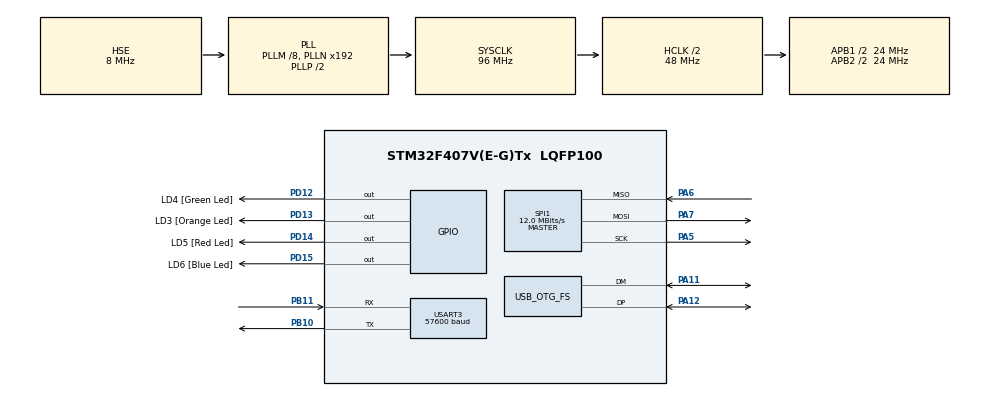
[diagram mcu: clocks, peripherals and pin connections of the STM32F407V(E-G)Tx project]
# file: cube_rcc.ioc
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Mcu.Family=STM32F4
Mcu.Name=STM32F407V(E-G)Tx
Mcu.Package=LQFP100
NVIC.PriorityGroup=NVIC_PRIORITYGROUP_0
PA11.Mode=Host_Only
PA11.Signal=USB_OTG_FS_DM
PA12.Mode=Host_Only
PA12.Signal=USB_OTG_FS_DP
PA5.Mode=Full_Duplex_Master
PA5.Signal=SPI1_SCK
PA6.Mode=Full_Duplex_Master
PA6.Signal=SPI1_MISO
PA7.Mode=Full_Duplex_Master
PA7.Signal=SPI1_MOSI
PB10.Mode=Asynchronous
PB10.Signal=USART3_TX
PB11.Mode=Asynchronous
PB11.Signal=USART3_RX
PD12.GPIO_Label=LD4 [Green Led]
PD12.GPIO_PuPd=GPIO_NOPULL
PD12.GPIO_Speed=GPIO_SPEED_FREQ_LOW
PD12.Signal=GPIO_Output
PD13.GPIO_Label=LD3 [Orange Led]
PD13.GPIO_PuPd=GPIO_NOPULL
PD13.GPIO_Speed=GPIO_SPEED_FREQ_LOW
PD13.Signal=GPIO_Output
PD14.GPIO_Label=LD5 [Red Led]
PD14.GPIO_PuPd=GPIO_NOPULL
PD14.GPIO_Speed=GPIO_SPEED_FREQ_LOW
PD14.Signal=GPIO_Output
PD15.GPIO_Label=LD6 [Blue Led]
PD15.GPIO_PuPd=GPIO_NOPULL
PD15.GPIO_Speed=GPIO_SPEED_FREQ_LOW
PD15.Signal=GPIO_Output
PH0-OSC_IN.GPIO_Label=PH0-OSC_IN
PH0-OSC_IN.Mode=HSE-External-Oscillator
PH0-OSC_IN.Signal=RCC_OSC_IN
PH1-OSC_OUT.GPIO_Label=PH1-OSC_OUT
PH1-OSC_OUT.Mode=HSE-External-Oscillator
PH1-OSC_OUT.Signal=RCC_OSC_OUT
ProjectManager.HeapSize=0x200
ProjectManager.StackSize=0x400
ProjectManager.TargetToolchain=STM32CubeIDE
RCC.48MHZClocksFreq_Value=48000000
RCC.AHBCLKDivider=RCC_SYSCLK_DIV2
RCC.AHBFreq_Value=48000000
RCC.APB1CLKDivider=RCC_HCLK_DIV2
RCC.APB1Freq_Value=24000000
RCC.APB1TimFreq_Value=48000000
RCC.APB2CLKDivider=RCC_HCLK_DIV2
RCC.APB2Freq_Value=24000000
RCC.APB2TimFreq_Value=48000000
RCC.CortexFreq_Value=48000000
RCC.HCLKFreq_Value=48000000
RCC.HSE_VALUE=8000000
RCC.HSI_VALUE=16000000
RCC.LSE_VALUE=32768
RCC.PLLM=8
RCC.SYSCLKFreq_VALUE=96000000
RCC.SYSCLKSource=RCC_SYSCLKSOURCE_PLLCLK
RCC.VCOOutputFreq_Value=192000000
SPI1.CalculateBaudRate=12.0 MBits/s
SPI1.Direction=SPI_DIRECTION_2LINES
SPI1.Mode=SPI_MODE_MASTER
SPI1.VirtualType=VM_MASTER
USART3.BaudRate=57600
USART3.VirtualMode=VM_ASYNC
USB_OTG_FS.VirtualMode=Host_Only
USB_OTG_FS.phy_itface=HCD_PHY_EMBEDDED
board=STM32F407G-DISC1

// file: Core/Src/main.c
/* USER CODE BEGIN Header */
/**
  ******************************************************************************
  * @file           : main.c
  * @brief          : Main program body
  ******************************************************************************
  * @attention
  *
  * <h2><center>&copy; Copyright (c) 2020 STMicroelectronics.
  * All rights reserved.</center></h2>
  *
  * This software component is licensed by ST under Ultimate Liberty license
  * SLA0044, the "License"; You may not use this file except in compliance with
  * the License. You may obtain a copy of the License at:
  *                             www.st.com/SLA0044
  *
  ******************************************************************************
  */
/* USER CODE END Header */

#include "main.h"

/* USER CODE BEGIN Includes */
#include "stdio.h"
#include "string.h"
/* USER CODE END Includes */

SPI_HandleTypeDef hspi1;

UART_HandleTypeDef huart3;

HCD_HandleTypeDef hhcd_USB_OTG_FS;

/* USER CODE BEGIN PV */
char msg_UART_TX [50];
/* USER CODE END PV */

void SystemClock_Config(void);
static void MX_GPIO_Init(void);
static void MX_USART3_UART_Init(void);
static void MX_USB_OTG_FS_HCD_Init(void);
static void MX_SPI1_Init(void);

int main(void)
{

  /* MCU Configuration--------------------------------------------------------*/

  /* Reset of all peripherals, Initializes the Flash interface and the Systick. */
  HAL_Init();

  /* Configure the system clock */
  SystemClock_Config();

  /* Initialize all configured peripherals */
  MX_GPIO_Init();
  MX_USART3_UART_Init();
  MX_USB_OTG_FS_HCD_Init();
  MX_SPI1_Init();
  /* USER CODE BEGIN 2 */
//  RCC_ClocksTypeDef RCC_Clocks;
  /* USER CODE END 2 */

  /* Infinite loop */
  while (1)
  {

    /* USER CODE BEGIN 3 */
	sprintf (msg_UART_TX, "%lu, %lu, %lu, %lu\r\n", HAL_RCC_GetSysClockFreq(), HAL_RCC_GetHCLKFreq(), HAL_RCC_GetPCLK1Freq(), HAL_RCC_GetPCLK2Freq());
	HAL_UART_Transmit (&huart3, (uint8_t*)msg_UART_TX, strlen(msg_UART_TX), 0xFF);
	HAL_Delay (1000);
  }
  /* USER CODE END 3 */
}

void SystemClock_Config(void)
{
  RCC_OscInitTypeDef RCC_OscInitStruct = {0};
  RCC_ClkInitTypeDef RCC_ClkInitStruct = {0};

  /** Configure the main internal regulator output voltage
  */
  __HAL_RCC_PWR_CLK_ENABLE();
  __HAL_PWR_VOLTAGESCALING_CONFIG(PWR_REGULATOR_VOLTAGE_SCALE1);
  /** Initializes the CPU, AHB and APB busses clocks
  */
  RCC_OscInitStruct.OscillatorType = RCC_OSCILLATORTYPE_HSE;
  RCC_OscInitStruct.HSEState = RCC_HSE_ON;
  RCC_OscInitStruct.PLL.PLLState = RCC_PLL_ON;
  RCC_OscInitStruct.PLL.PLLSource = RCC_PLLSOURCE_HSE;
  RCC_OscInitStruct.PLL.PLLM = 8;
  RCC_OscInitStruct.PLL.PLLN = 192;
  RCC_OscInitStruct.PLL.PLLP = RCC_PLLP_DIV2;
  RCC_OscInitStruct.PLL.PLLQ = 4;
  if (HAL_RCC_OscConfig(&RCC_OscInitStruct) != HAL_OK)
  {
    Error_Handler();
  }
  /** Initializes the CPU, AHB and APB busses clocks
  */
  RCC_ClkInitStruct.ClockType = RCC_CLOCKTYPE_HCLK|RCC_CLOCKTYPE_SYSCLK
                              |RCC_CLOCKTYPE_PCLK1|RCC_CLOCKTYPE_PCLK2;
  RCC_ClkInitStruct.SYSCLKSource = RCC_SYSCLKSOURCE_PLLCLK;
  RCC_ClkInitStruct.AHBCLKDivider = RCC_SYSCLK_DIV2;
  RCC_ClkInitStruct.APB1CLKDivider = RCC_HCLK_DIV2;
  RCC_ClkInitStruct.APB2CLKDivider = RCC_HCLK_DIV2;

  if (HAL_RCC_ClockConfig(&RCC_ClkInitStruct, FLASH_LATENCY_1) != HAL_OK)
  {
    Error_Handler();
  }
}

static void MX_SPI1_Init(void)
{

  /* SPI1 parameter configuration*/
  hspi1.Instance = SPI1;
  hspi1.Init.Mode = SPI_MODE_MASTER;
  hspi1.Init.Direction = SPI_DIRECTION_2LINES;
  hspi1.Init.DataSize = SPI_DATASIZE_8BIT;
  hspi1.Init.CLKPolarity = SPI_POLARITY_LOW;
  hspi1.Init.CLKPhase = SPI_PHASE_1EDGE;
  hspi1.Init.NSS = SPI_NSS_SOFT;
  hspi1.Init.BaudRatePrescaler = SPI_BAUDRATEPRESCALER_2;
  hspi1.Init.FirstBit = SPI_FIRSTBIT_MSB;
  hspi1.Init.TIMode = SPI_TIMODE_DISABLE;
  hspi1.Init.CRCCalculation = SPI_CRCCALCULATION_DISABLE;
  hspi1.Init.CRCPolynomial = 10;
  if (HAL_SPI_Init(&hspi1) != HAL_OK)
  {
    Error_Handler();
  }

}

static void MX_USART3_UART_Init(void)
{

  huart3.Instance = USART3;
  huart3.Init.BaudRate = 57600;
  huart3.Init.WordLength = UART_WORDLENGTH_8B;
  huart3.Init.StopBits = UART_STOPBITS_1;
  huart3.Init.Parity = UART_PARITY_NONE;
  huart3.Init.Mode = UART_MODE_TX_RX;
  huart3.Init.HwFlowCtl = UART_HWCONTROL_NONE;
  huart3.Init.OverSampling = UART_OVERSAMPLING_16;
  if (HAL_UART_Init(&huart3) != HAL_OK)
  {
    Error_Handler();
  }

}

static void MX_USB_OTG_FS_HCD_Init(void)
{

  hhcd_USB_OTG_FS.Instance = USB_OTG_FS;
  hhcd_USB_OTG_FS.Init.Host_channels = 8;
  hhcd_USB_OTG_FS.Init.speed = HCD_SPEED_FULL;
  hhcd_USB_OTG_FS.Init.dma_enable = DISABLE;
  hhcd_USB_OTG_FS.Init.phy_itface = HCD_PHY_EMBEDDED;
  hhcd_USB_OTG_FS.Init.Sof_enable = DISABLE;
  if (HAL_HCD_Init(&hhcd_USB_OTG_FS) != HAL_OK)
  {
    Error_Handler();
  }

}

static void MX_GPIO_Init(void)
{
  GPIO_InitTypeDef GPIO_InitStruct = {0};

  /* GPIO Ports Clock Enable */
  __HAL_RCC_GPIOH_CLK_ENABLE();
  __HAL_RCC_GPIOA_CLK_ENABLE();
  __HAL_RCC_GPIOB_CLK_ENABLE();
  __HAL_RCC_GPIOD_CLK_ENABLE();

  /*Configure GPIO pin Output Level */
  HAL_GPIO_WritePin(GPIOD, LD4_Pin|LD3_Pin|LD5_Pin|LD6_Pin, GPIO_PIN_RESET);

  /*Configure GPIO pins : LD4_Pin LD3_Pin LD5_Pin LD6_Pin */
  GPIO_InitStruct.Pin = LD4_Pin|LD3_Pin|LD5_Pin|LD6_Pin;
  GPIO_InitStruct.Mode = GPIO_MODE_OUTPUT_PP;
  GPIO_InitStruct.Pull = GPIO_NOPULL;
  GPIO_InitStruct.Speed = GPIO_SPEED_FREQ_LOW;
  HAL_GPIO_Init(GPIOD, &GPIO_InitStruct);

}

void Error_Handler(void)
{
}

/************************ (C) COPYRIGHT STMicroelectronics *****END OF FILE****/
